# CPSW_WR register map
Vendor: Texas Instruments
Peripheral module from a debugger description file (folder am437x).
Registers are 32-bit, access per field, no defined reset value unless marked. A register's access mark holds for its fields unless they carry their own. Offsets are as the file gives them; lines under a group give offsets from that group; [hi:lo] are bit positions; {n}, {i} and the like mark numbered series; 'fields as' and 'values as' point back to an identical list; <NAME> marks a mode.

## CPSW_WR
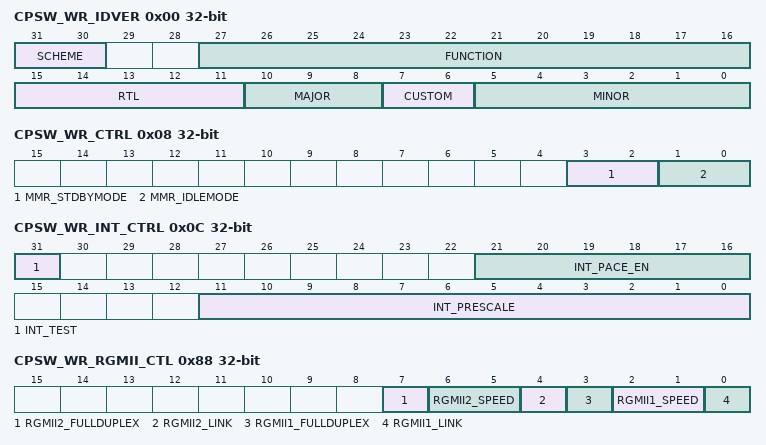
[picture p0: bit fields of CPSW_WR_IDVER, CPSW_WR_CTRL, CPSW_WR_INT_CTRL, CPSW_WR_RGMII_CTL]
0x00 CPSW_WR_IDVER ro — SUBSYSTEM ID VERSION REGISTER
  [31:30] SCHEME — Scheme value
  [27:16] FUNCTION — function value
  [15:11] RTL — rtl version
  [10:8] MAJOR — major version
  [7:6] CUSTOM — custom version
  [5:0] MINOR — minor version
0x04 CPSW_WR_SOFT_RESET — SUBSYSTEM SOFT RESET REGISTER
  [0] SOFT_RESET rw — Software reset - Writing a one to this bit causes the CPGMACSS_R logic to be reset (INT, REGS, CPPI). [[br]]Software reset occurs on the clock following the register bit write. [[br]]
0x08 CPSW_WR_CTRL — SUBSYSTEM CONTROL REGISTER
  [3:2] MMR_STDBYMODE rw — Configuration of the local initiator state management mode. [[br]]By definition, initiator may generate read/write transaction as long as it is out of STANDBY state. [[br]]
    3=en_4_0x3 (Reserved : Reserved.); 2=en_3_0x2 (Reserved : Reserved.); 1=en_2_0x1 (No-standby mode : Local initiator is unconditionally placed out of standby state.); 0=en_1_0x0 (Force-standby mode : Local initiator is unconditionally placed in standbystate.)
  [1:0] MMR_IDLEMODE rw — Configuration of the local initiator state management mode. [[br]]By definition, initiator may generate read/write transaction as long as it is out of IDLE state. [[br]]
    3=en_4_0x3 (Reserved : Reserved.); 2=en_3_0x2 (Reserved : Reserved.); 1=en_2_0x1 (No-idle mode : Local initiator is unconditionally placed out of idle state.); 0=en_1_0x0 (Force-idle mode : Local initiator is unconditionally placed in idle state.)
0x0C CPSW_WR_INT_CTRL — SUBSYSTEM INTERRUPT CONTROL
  [31] INT_TEST rw — Interrupt Test - Test bit to the interrupt pacing blocks
  [21:16] INT_PACE_EN rw — ARRAY(0x1b8eec0)
  [11:0] INT_PRESCALE ro — Interrupt Counter Prescaler - The number of MAIN_CLK periods in 4us.
{0x10+0x10*i} CPSW_WR_C{i}_RX_THRESH_EN (i=0..2) — SUBSYSTEM CORE {i} RECEIVE THRESHOLD INT ENABLE REGISTER
  [7:0] C{i}_RX_THRESH_EN rw — Core {i} Receive Threshold Enable - Each bit in this register corresponds to the bit in the receive threshold interrupt that is enabled to generate an interrupt on C{i}_RX_THRESH_PULSE. [[br]]
{0x14+0x10*i} CPSW_WR_C{i}_RX_EN (i=0..2) — SUBSYSTEM CORE {i} RECEIVE INTERRUPT ENABLE REGISTER
  [7:0] C{i}_RX_EN rw — Core {i} Receive Enable - Each bit in this register corresponds to the bit in the rx interrupt that is enabled to generate an interrupt on C{i}_RX_PULSE. [[br]]
{0x18+0x10*i} CPSW_WR_C{i}_TX_EN (i=0..2) — SUBSYSTEM CORE {i} TRANSMIT INTERRUPT ENABLE REGISTER
  [7:0] C{i}_TX_EN rw — Core {i} Transmit Enable - Each bit in this register corresponds to the bit in the tx interrupt that is enabled to generate an interrupt on C{i}_TX_PULSE. [[br]]
{0x1C+0x10*i} CPSW_WR_C{i}_MISC_EN (i=0..2) — SUBSYSTEM CORE {i} MISC INTERRUPT ENABLE REGISTER
  [4:0] C{i}_MISC_EN rw — Core {i} Misc Enable - Each bit in this register corresponds to the miscellaneous interrupt (evnt_pend, stat_pend, host_pend, mdio_linkint, mdio_userint) that is enabled to generate an interrupt on C{i}_Misc_PULSE. [[br]]
0x40 CPSW_WR_C0_RX_THRESH_STAT ro — SUBSYSTEM CORE 0 RX THRESHOLD MASKED INT STATUS REGISTER
  [7:0] C0_RX_THRESH_STAT — Core 0 Receive Threshold Masked Interrupt Status - Each bit in this read only register corresponds to the bit in the receive threshold interrupt that is enabled and generating an interrupt on C0_RX_THRESH_PULSE. [[br]]
0x44 CPSW_WR_C0_RX_STAT ro — SUBSYSTEM CORE 0 RX INTERRUPT MASKED INT STATUS REGISTER
  [7:0] C0_RX_STAT — Core 0 Receive Masked Interrupt Status - Each bit in this read only register corresponds to the bit in the Rx interrupt that is enabled and generating an interrupt on C0_RX_PULSE. [[br]]
0x48 CPSW_WR_C0_TX_STAT ro — SUBSYSTEM CORE 0 TX INTERRUPT MASKED INT STATUS REGISTER
  [7:0] C0_TX_STAT — Core 0 Transmit Masked Interrupt Status - Each bit in this read only register corresponds to the bit in the Tx interrupt that is enabled and generating an interrupt on C0_TX_PULSE . [[br]]
0x4C CPSW_WR_C0_MISC_STAT ro — SUBSYSTEM CORE 0 MISC INTERRUPT MASKED INT STATUS REGISTER
  [6:0] C0_MISC_STAT — Core 0 Misc Masked Interrupt Status - Each bit in this register corresponds to the miscellaneous interrupt (evnt_pend, stat_pend, host_pend, mdio_linkint, mdio_userint) that is enabled and generating an interrupt on C0_MISC_PULSE . [[br]]
0x50 CPSW_WR_C1_RX_THRESH_STAT ro — SUBSYSTEM CORE 1 RX THRESHOLD MASKED INT STATUS REGISTER
  [7:0] C1_RX_THRESH_STAT — Core 1 Receive Threshold Masked Interrupt Status - Each bit in this register corresponds to the bit in the receive threshold interrupt that is enabled and generating an interrupt on C1_RX_THRESH_PULSE. [[br]]
0x54 CPSW_WR_C1_RX_STAT ro — SUBSYSTEM CORE 1 RECEIVE MASKED INTERRUPT STATUS REGISTER
  [7:0] C1_RX_STAT — Core 1 Receive Masked Interrupt Status - Each bit in this register corresponds to the bit in the Rx interrupt that is enabled and generating an interrupt on C1_RX_PULSE. [[br]]
0x58 CPSW_WR_C1_TX_STAT ro — SUBSYSTEM CORE 1 TRANSMIT MASKED INTERRUPT STATUS REGISTER
  [7:0] C1_TX_STAT — Core 1 Transmit Masked Interrupt Status - Each bit in this register corresponds to the bit in the Tx interrupt that is enabled and generating an interrupt on C1_TX_PULSE. [[br]]
0x5C CPSW_WR_C1_MISC_STAT ro — SUBSYSTEM CORE 1 MISC MASKED INTERRUPT STATUS REGISTER
  [6:0] C1_MISC_STAT — Core 1 Misc Masked Interrupt Status - Each bit in this register corresponds to the miscellaneous interrupt (evnt_pend, stat_pend, host_pend, mdio_linkint, mdio_userint) that is enabled and generating an interrupt on C1_MISC_PULSE . [[br]]
0x60 CPSW_WR_C2_RX_THRESH_STAT ro — SUBSYSTEM CORE 2 RX THRESHOLD MASKED INT STATUS REGISTER
  [7:0] C2_RX_THRESH_STAT — Core 2 Receive Threshold Masked Interrupt Status - Each bit in this register corresponds to the bit in the receive threshold interrupt that is enabled and generating an interrupt on C2_RX_THRESH_PULSE. [[br]]
0x64 CPSW_WR_C2_RX_STAT ro — SUBSYSTEM CORE 2 RECEIVE MASKED INTERRUPT STATUS REGISTER
  [7:0] C2_RX_STAT — Core 2 Receive Masked Interrupt Status - Each bit in this register corresponds to the bit in the Rx interrupt that is enabled and generating an interrupt on C2_RX_PULSE. [[br]]
0x68 CPSW_WR_C2_TX_STAT ro — SUBSYSTEM CORE 2 TRANSMIT MASKED INTERRUPT STATUS REGISTER
  [7:0] C2_TX_STAT — Core 2 Transmit Masked Interrupt Status - Each bit in this register corresponds to the bit in the Tx interrupt that is enabled and generating an interrupt on C2_TX_PULSE. [[br]]
0x6C CPSW_WR_C2_MISC_STAT ro — SUBSYSTEM CORE 2 MISC MASKED INTERRUPT STATUS REGISTER
  [6:0] C2_MISC_STAT — Core 2 Misc Masked Interrupt Status - Each bit in this register corresponds to the miscellaneous interrupt (evnt_pend, stat_pend, host_pend, mdio_linkint, mdio_userint) that is enabled and generating an interrupt on C2_MISC_PULSE . [[br]]
{0x70+8i} CPSW_WR_C{i}_RX_IMAX (i=0..2) — SUBSYSTEM CORE {i} RECEIVE INTERRUPTS PER MILLISECOND
  [5:0] C{i}_RX_IMAX rw — Core {i} Receive Interrupts per Millisecond - The maximum number of interrupts per millisecond generated on C{i}_RX_PULSE if pacing is enabled for this interrupt. [[br]]
{0x74+8i} CPSW_WR_C{i}_TX_IMAX (i=0..2) — SUBSYSTEM CORE {i} TRANSMIT INTERRUPTS PER MILLISECOND
  [5:0] C{i}_TX_IMAX rw — Core {i} Transmit Interrupts per Millisecond - The maximum number of interrupts per millisecond generated on C{i}_TX_PULSE if pacing is enabled for this interrupt. [[br]]
0x88 CPSW_WR_RGMII_CTL ro — RGMII CONTROL SIGNAL REGISTER
  [7] RGMII2_FULLDUPLEX — RGMII 2 Fullduplex - This is the CPRGMII fullduplex output signal. [[br]]
    1=en_2_0x1 (Full-duplex mode); 0=en_1_0x0 (Half-duplex mode)
  [6:5] RGMII2_SPEED — RGMII2 Speed - This is the CPRGMI speed output signal
    3=en_4_0x3 (Reserved); 2=en_3_0x2 (1000Mbps (gig) mode); 1=en_2_0x1 (100Mbps mode); 0=en_1_0x0 (10Mbps mode)
  [4] RGMII2_LINK — RGMII2 Link Indicator - This is the CPRGMII link output signal
    1=en_2_0x1 (RGMII2 link is up); 0=en_1_0x0 (RGMII2 link is down)
  [3] RGMII1_FULLDUPLEX — RGMII1 Fullduplex - This is the CPRGMII fullduplex output signal.
    1=en_2_0x1 (Full-duplex mode); 0=en_1_0x0 (Half-duplex mode)
  [2:1] RGMII1_SPEED — RGMII1 Speed - This is the CPRGMII speed output signal
    values as RGMII2_SPEED
  [0] RGMII1_LINK — RGMII1 Link Indicator - This is the CPRGMII link output signal
    1=en_2_0x1 (RGMII1 link is up); 0=en_1_0x0 (RGMII1 link is down)
